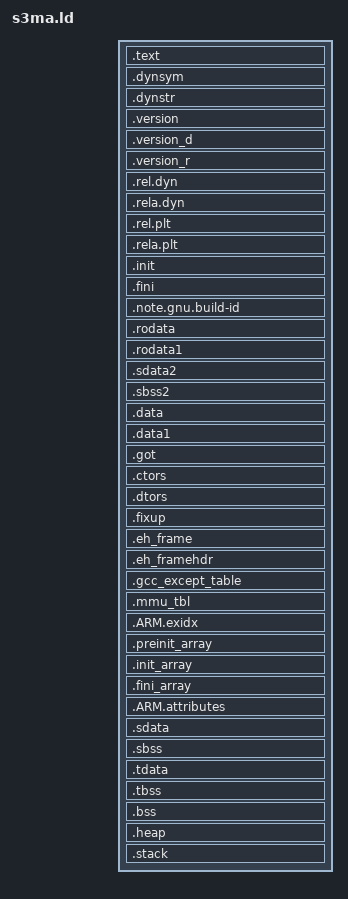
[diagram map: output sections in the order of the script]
/*******************************************************************/
/* Linker file for the Harris S3MA Cortex A9                       */
/*******************************************************************/


/* Specify the default entry point to the program */

ENTRY(_freertos_vector_table)

/* Define the sections, and where they are mapped in memory */

SECTIONS
{
.text : {
   __isr_vector_start = .;
   *(.freertos_vectors)
   __isr_vector_end = .;
   *(.boot)
   *(.text)
   *(.text.*)
   *(.gnu.linkonce.t.*)
   *(.plt)
   *(.gnu_warning)
   *(.gcc_execpt_table)
   *(.glue_7)
   *(.glue_7t)
   *(.vfp11_veneer)
   *(.ARM.extab)
   *(.gnu.linkonce.armextab.*)
} > ddr

.dynsym         : { *(.dynsym) } > ddr
.dynstr         : { *(.dynstr) } > ddr
.version        : { *(.version) } > ddr
.version_d      : { *(.version_d) } > ddr
.version_r      : { *(.version_r) } > ddr
.rel.dyn        : { *(.rel.dyn) } > ddr
.rela.dyn       : { *(.rela.dyn) } > ddr
.rel.plt        : { *(.rel.plt) } > ddr
.rela.plt       : { *(.rela.plt) } > ddr

.init : {
   KEEP (*(.init))
} > ddr

.fini : {
   KEEP (*(.fini))
} > ddr

.note.gnu.build-id :
{
  . = ALIGN(4);
  PROVIDE( _note = .);
  *(.note.gnu.build-id)
  . = ALIGN(4);
  *(.note.gnu.build-id.*);
  . = ALIGN(4);
  PROVIDE( _enote = .);
} > ddr

.rodata : {
   __rodata_start = .;
   *(.rodata)
   *(.rodata.*)
   *(.gnu.linkonce.r.*)
   __rodata_end = .;
} > ddr

.rodata1 : {
   __rodata1_start = .;
   *(.rodata1)
   *(.rodata1.*)
   __rodata1_end = .;
} > ddr

.sdata2 : {
   __sdata2_start = .;
   *(.sdata2)
   *(.sdata2.*)
   *(.gnu.linkonce.s2.*)
   __sdata2_end = .;
} > ddr

.sbss2 : {
   __sbss2_start = .;
   *(.sbss2)
   *(.sbss2.*)
   *(.gnu.linkonce.sb2.*)
   __sbss2_end = .;
} > ddr

.data : {
   __data_start = .;
   *(.data)
   *(.data.*)
   *(.gnu.linkonce.d.*)
   *(.jcr)
   __data_end = .;
} > ddr

.data1 : {
   __data1_start = .;
   *(.data1)
   *(.data1.*)
   __data1_end = .;
} > ddr

.got : {
   *(.got)
   *(.got.plt)
} > ddr

.ctors : {
   __CTOR_LIST__ = .;
   ___CTORS_LIST___ = .;
   KEEP (*crtbegin.o(.ctors))
   KEEP (*(EXCLUDE_FILE(*crtend.o) .ctors))
   KEEP (*(SORT(.ctors.*)))
   KEEP (*(.ctors))
   __CTOR_END__ = .;
   ___CTORS_END___ = .;
} > ddr

.dtors : {
   __DTOR_LIST__ = .;
   ___DTORS_LIST___ = .;
   KEEP (*crtbegin.o(.dtors))
   KEEP (*(EXCLUDE_FILE(*crtend.o) .dtors))
   KEEP (*(SORT(.dtors.*)))
   KEEP (*(.dtors))
   __DTOR_END__ = .;
   ___DTORS_END___ = .;
} > ddr

.fixup : {
   __fixup_start = .;
   *(.fixup)
   __fixup_end = .;
} > ddr

.eh_frame : {
   *(.eh_frame)
} > ddr

.eh_framehdr : {
   __eh_framehdr_start = .;
   *(.eh_framehdr)
   __eh_framehdr_end = .;
} > ddr

.gcc_except_table : {
   *(.gcc_except_table)
} > ddr

.mmu_tbl (ALIGN(16384)) : {
   __mmu_tbl_start = .;
   *(.mmu_tbl)
   __mmu_tbl_end = .;
} > ddr

.ARM.exidx : {
   __exidx_start = .;
   *(.ARM.exidx*)
   *(.gnu.linkonce.armexidix.*.*)
   __exidx_end = .;
} > ddr

.preinit_array : {
   __preinit_array_start = .;
   KEEP (*(SORT(.preinit_array.*)))
   KEEP (*(.preinit_array))
   __preinit_array_end = .;
} > ddr

.init_array : {
   __init_array_start = .;
   KEEP (*(SORT(.init_array.*)))
   KEEP (*(.init_array))
   __init_array_end = .;
} > ddr

.fini_array : {
   __fini_array_start = .;
   KEEP (*(SORT(.fini_array.*)))
   KEEP (*(.fini_array))
   __fini_array_end = .;
} > ddr

.ARM.attributes : {
   __ARM.attributes_start = .;
   *(.ARM.attributes)
   __ARM.attributes_end = .;
} > ddr

.sdata : {
   __sdata_start = .;
   *(.sdata)
   *(.sdata.*)
   *(.gnu.linkonce.s.*)
   __sdata_end = .;
} > ddr

.sbss (NOLOAD) : {
   __sbss_start = .;
   *(.sbss)
   *(.sbss.*)
   *(.gnu.linkonce.sb.*)
   __sbss_end = .;
} > ddr

.tdata : {
   __tdata_start = .;
   *(.tdata)
   *(.tdata.*)
   *(.gnu.linkonce.td.*)
   __tdata_end = .;
} > ddr

.tbss : {
   __tbss_start = .;
   *(.tbss)
   *(.tbss.*)
   *(.gnu.linkonce.tb.*)
   __tbss_end = .;
} > ddr

.bss (NOLOAD) : {
   __bss_start = .;
   *(.bss)
   *(.bss.*)
   *(.gnu.linkonce.b.*)
   *(COMMON)
   __bss_end = .;
} > ddr

_SDA_BASE_ = __sdata_start + ((__sbss_end - __sdata_start) / 2 );

_SDA2_BASE_ = __sdata2_start + ((__sbss2_end - __sdata2_start) / 2 );

/* Generate Stack and Heap definitions */

.heap (NOLOAD) : {
   . = ALIGN(16);
   _heap = .;
   HeapBase = .;
   _heap_start = .;
   . += _HEAP_SIZE;
   _heap_end = .;
   HeapLimit = .;
} > ddr

.stack (NOLOAD) : {
   . = ALIGN(16);
   _stack_end = .;
   . += _STACK_SIZE;
   _stack = .;
   __stack = _stack;
   . = ALIGN(16);
   _irq_stack_end = .;
   . += _STACK_SIZE;
   __irq_stack = .;
   _supervisor_stack_end = .;
   . += _SUPERVISOR_STACK_SIZE;
   . = ALIGN(16);
   __supervisor_stack = .;
   _abort_stack_end = .;
   . += _ABORT_STACK_SIZE;
   . = ALIGN(16);
   __abort_stack = .;
   _fiq_stack_end = .;
   . += _FIQ_STACK_SIZE;
   . = ALIGN(16);
   __fiq_stack = .;
   _undef_stack_end = .;
   . += _UNDEF_STACK_SIZE;
   . = ALIGN(16);
   __undef_stack = .;
} > ddr

_end = .;
}

